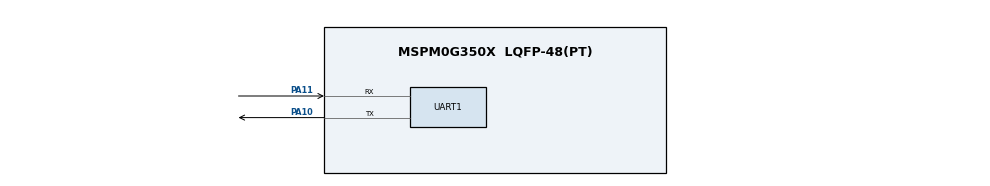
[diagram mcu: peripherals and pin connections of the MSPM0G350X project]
/**
 * @cliArgs --device "MSPM0G350X" --part "Default" --package "LQFP-48(PT)" --product "mspm0_sdk@2.04.00.06"
 * @versions {"tool":"1.23.0+4000"}
 */
scripting.excludeFromBuild("device.lds.genlibs");

/**
 * Import the modules used in this configuration.
 */
const GPIO          = scripting.addModule("/ti/driverlib/GPIO", {}, false);
const GPIO1         = GPIO.addInstance();
const GPIO2         = GPIO.addInstance();
const SYSCTL        = scripting.addModule("/ti/driverlib/SYSCTL");
const SYSTICK       = scripting.addModule("/ti/driverlib/SYSTICK");
const UART          = scripting.addModule("/ti/driverlib/UART", {}, false);
const UART1         = UART.addInstance();
const ProjectConfig = scripting.addModule("/ti/project_config/ProjectConfig");

/**
 * Write custom configuration values to the imported modules.
 */
const gate7  = system.clockTree["MFCLKGATE"];
gate7.enable = true;

GPIO1.port                               = "PORTA";
GPIO1.$name                              = "KEY";
GPIO1.associatedPins[0].internalResistor = "PULL_DOWN";
GPIO1.associatedPins[0].direction        = "INPUT";
GPIO1.associatedPins[0].$name            = "PIN_17";
GPIO1.associatedPins[0].assignedPin      = "17";
GPIO1.associatedPins[0].interruptEn      = true;
GPIO1.associatedPins[0].polarity         = "RISE";

const Board = scripting.addModule("/ti/driverlib/Board", {}, false);

GPIO2.$name                         = "LED";
GPIO2.port                          = "PORTA";
GPIO2.associatedPins[0].$name       = "PIN_14";
GPIO2.associatedPins[0].assignedPin = "14";

SYSCTL.clockTreeEn = true;

SYSTICK.periodEnable    = true;
SYSTICK.period          = 32000;
SYSTICK.interruptEnable = true;
SYSTICK.systickEnable   = true;

UART1.$name                    = "UART_0";
UART1.uartClkSrc               = "MFCLK";
UART1.enabledInterrupts        = ["RX"];
UART1.peripheral.$assign       = "UART0";
UART1.peripheral.rxPin.$assign = "PA11";
UART1.peripheral.txPin.$assign = "PA10";
UART1.txPinConfig.$name        = "ti_driverlib_gpio_GPIOPinGeneric0";
UART1.rxPinConfig.$name        = "ti_driverlib_gpio_GPIOPinGeneric1";

ProjectConfig.compiler = "gcc";

/**
 * Pinmux solution for unlocked pins/peripherals. This ensures that minor changes to the automatic solver in a future
 * version of the tool will not impact the pinmux you originally saw.  These lines can be completely deleted in order to
 * re-solve from scratch.
 */
GPIO1.associatedPins[0].pin.$suggestSolution = "PA17";
Board.peripheral.$suggestSolution            = "DEBUGSS";
Board.peripheral.swclkPin.$suggestSolution   = "PA20";
Board.peripheral.swdioPin.$suggestSolution   = "PA19";
GPIO2.associatedPins[0].pin.$suggestSolution = "PA14";
